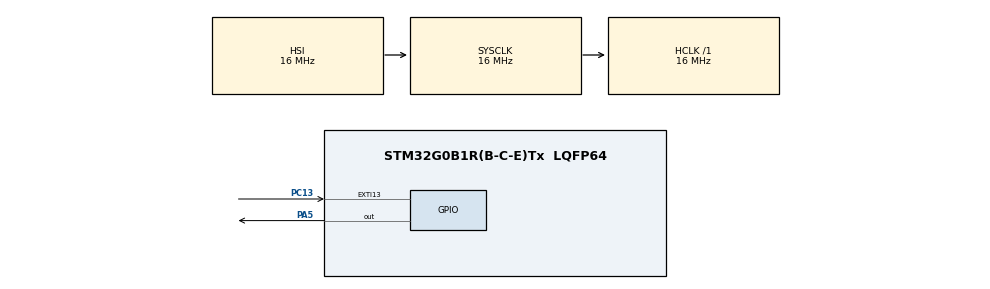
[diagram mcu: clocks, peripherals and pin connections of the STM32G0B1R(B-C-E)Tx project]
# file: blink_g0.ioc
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Mcu.Family=STM32G0
Mcu.Name=STM32G0B1R(B-C-E)Tx
Mcu.Package=LQFP64
NVIC.EXTI4_15_IRQn=true\:0\:0\:false\:false\:true\:true\:true\:true
NVIC.RTC_TAMP_IRQn=true\:0\:0\:false\:false\:true\:true\:true\:true
PA13.GPIO_Label=TMS
PA13.Signal=SYS_SWDIO
PA14-BOOT0.GPIO_Label=TCK
PA14-BOOT0.Signal=SYS_SWCLK
PA2.GPIO_Label=USART2_TX [STLK_TX]
PA2.Signal=USART2_TX
PA3.GPIO_Label=USART2_RX [STLK_RX]
PA3.Signal=USART2_RX
PA5.Signal=GPIO_Output
PC13.Signal=GPXTI13
PC14-OSC32_IN\ (PC14).Mode=LSE-External-Oscillator
PC14-OSC32_IN\ (PC14).Signal=RCC_OSC32_IN
PC15-OSC32_OUT\ (PC15).Mode=LSE-External-Oscillator
PC15-OSC32_OUT\ (PC15).Signal=RCC_OSC32_OUT
PF0-OSC_IN\ (PF0).GPIO_Label=MCO
PF0-OSC_IN\ (PF0).Signal=RCC_OSC_IN
ProjectManager.HeapSize=0x200
ProjectManager.StackSize=0x400
ProjectManager.TargetToolchain=STM32CubeIDE
RCC.AHBFreq_Value=16000000
RCC.CortexFreq_Value=16000000
RCC.EXTERNAL_CLOCK_VALUE=12288000
RCC.HCLKFreq_Value=16000000
RCC.HSE_VALUE=8000000
RCC.HSI48_VALUE=48000000
RCC.HSI_VALUE=16000000
RCC.MSICalibrationValue=18
RCC.RTCClockSelection=RCC_RTCCLKSOURCE_LSE
RCC.SYSCLKFreq_VALUE=16000000
RCC.USBFreq_Value=48000000
RCC.VCOOutputFreq_Value=128000000
RTC.WakeUpCounter-WakeUp=10246
VP_RTC_VS_RTC_Activate.Mode=RTC_Enabled
VP_RTC_VS_RTC_WakeUp_intern.Mode=WakeUp
VP_SYS_VS_DBSignals.Mode=DisableDeadBatterySignals
board=NUCLEO-G0B1RE

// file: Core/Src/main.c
/* USER CODE BEGIN Header */
/**
  ******************************************************************************
  * @file           : main.c
  * @brief          : Main program body
  ******************************************************************************
  * @attention
  *
  * Copyright (c) 2024 STMicroelectronics.
  * All rights reserved.
  *
  * This software is licensed under terms that can be found in the LICENSE file
  * in the root directory of this software component.
  * If no LICENSE file comes with this software, it is provided AS-IS.
  *
  ******************************************************************************
  */
/* USER CODE END Header */
#include "main.h"

/* USER CODE BEGIN PM */

uint8_t PC13_flag = 0;

/* USER CODE END PM */

RTC_HandleTypeDef hrtc;

void SystemClock_Config(void);
static void MX_GPIO_Init(void);
static void MX_RTC_Init(void);

int main(void)
{

  /* MCU Configuration--------------------------------------------------------*/

  /* Reset of all peripherals, Initializes the Flash interface and the Systick. */
  HAL_Init();

  /* Configure the system clock */
  SystemClock_Config();

  /* Initialize all configured peripherals */
  MX_GPIO_Init();
  MX_RTC_Init();
  /* USER CODE BEGIN 2 */

 // HAL_TIM_PWM_Start(&htim2, TIM_CHANNEL_1);

  /* USER CODE END 2 */

  /* Infinite loop */
  while (1)
  {

    /* USER CODE BEGIN 3 */

	  HAL_GPIO_WritePin(GPIOA, GPIO_PIN_5, GPIO_PIN_SET);
	      HAL_Delay(1000);
	      HAL_GPIO_WritePin(GPIOA, GPIO_PIN_5, GPIO_PIN_RESET);

	      // enter STOP mode
	      HAL_PWR_EnterSTOPMode(PWR_LOWPOWERREGULATOR_ON, PWR_STOPENTRY_WFI);

	      // reconfigure system clock
	      SystemClock_Config();
	      /* USER CODE END WHILE */

	      /* USER CODE BEGIN 3 */

	  //HAL_GPIO_TogglePin(GPIOA, GPIO_PIN_5);
	  //HAL_Delay(1000);

  }
  /* USER CODE END 3 */
}

void SystemClock_Config(void)
{
  RCC_OscInitTypeDef RCC_OscInitStruct = {0};
  RCC_ClkInitTypeDef RCC_ClkInitStruct = {0};

  /** Configure the main internal regulator output voltage
  */
  HAL_PWREx_ControlVoltageScaling(PWR_REGULATOR_VOLTAGE_SCALE1);

  /** Configure LSE Drive Capability
  */
  HAL_PWR_EnableBkUpAccess();
  __HAL_RCC_LSEDRIVE_CONFIG(RCC_LSEDRIVE_LOW);

  /** Initializes the RCC Oscillators according to the specified parameters
  * in the RCC_OscInitTypeDef structure.
  */
  RCC_OscInitStruct.OscillatorType = RCC_OSCILLATORTYPE_HSI|RCC_OSCILLATORTYPE_LSE;
  RCC_OscInitStruct.LSEState = RCC_LSE_ON;
  RCC_OscInitStruct.HSIState = RCC_HSI_ON;
  RCC_OscInitStruct.HSIDiv = RCC_HSI_DIV1;
  RCC_OscInitStruct.HSICalibrationValue = RCC_HSICALIBRATION_DEFAULT;
  RCC_OscInitStruct.PLL.PLLState = RCC_PLL_NONE;
  if (HAL_RCC_OscConfig(&RCC_OscInitStruct) != HAL_OK)
  {
    Error_Handler();
  }

  /** Initializes the CPU, AHB and APB buses clocks
  */
  RCC_ClkInitStruct.ClockType = RCC_CLOCKTYPE_HCLK|RCC_CLOCKTYPE_SYSCLK
                              |RCC_CLOCKTYPE_PCLK1;
  RCC_ClkInitStruct.SYSCLKSource = RCC_SYSCLKSOURCE_HSI;
  RCC_ClkInitStruct.AHBCLKDivider = RCC_SYSCLK_DIV1;
  RCC_ClkInitStruct.APB1CLKDivider = RCC_HCLK_DIV1;

  if (HAL_RCC_ClockConfig(&RCC_ClkInitStruct, FLASH_LATENCY_0) != HAL_OK)
  {
    Error_Handler();
  }
}

static void MX_RTC_Init(void)
{

  /** Initialize RTC Only
  */
  hrtc.Instance = RTC;
  hrtc.Init.HourFormat = RTC_HOURFORMAT_24;
  hrtc.Init.AsynchPrediv = 127;
  hrtc.Init.SynchPrediv = 255;
  hrtc.Init.OutPut = RTC_OUTPUT_DISABLE;
  hrtc.Init.OutPutRemap = RTC_OUTPUT_REMAP_NONE;
  hrtc.Init.OutPutPolarity = RTC_OUTPUT_POLARITY_HIGH;
  hrtc.Init.OutPutType = RTC_OUTPUT_TYPE_OPENDRAIN;
  hrtc.Init.OutPutPullUp = RTC_OUTPUT_PULLUP_NONE;
  if (HAL_RTC_Init(&hrtc) != HAL_OK)
  {
    Error_Handler();
  }

  /** Enable the WakeUp
  */
  if (HAL_RTCEx_SetWakeUpTimer_IT(&hrtc, 10246, RTC_WAKEUPCLOCK_RTCCLK_DIV16) != HAL_OK)
  {
    Error_Handler();
  }

}

static void MX_GPIO_Init(void)
{
  GPIO_InitTypeDef GPIO_InitStruct = {0};

  /* GPIO Ports Clock Enable */
  __HAL_RCC_GPIOC_CLK_ENABLE();
  __HAL_RCC_GPIOF_CLK_ENABLE();
  __HAL_RCC_GPIOA_CLK_ENABLE();

  /*Configure GPIO pin Output Level */
  HAL_GPIO_WritePin(GPIOA, GPIO_PIN_5, GPIO_PIN_RESET);

  /*Configure GPIO pin : PC13 */
  GPIO_InitStruct.Pin = GPIO_PIN_13;
  GPIO_InitStruct.Mode = GPIO_MODE_IT_RISING;
  GPIO_InitStruct.Pull = GPIO_NOPULL;
  HAL_GPIO_Init(GPIOC, &GPIO_InitStruct);

  /*Configure GPIO pins : USART2_TX_Pin USART2_RX_Pin */
  GPIO_InitStruct.Pin = USART2_TX_Pin|USART2_RX_Pin;
  GPIO_InitStruct.Mode = GPIO_MODE_AF_PP;
  GPIO_InitStruct.Pull = GPIO_NOPULL;
  GPIO_InitStruct.Speed = GPIO_SPEED_FREQ_LOW;
  GPIO_InitStruct.Alternate = GPIO_AF1_USART2;
  HAL_GPIO_Init(GPIOA, &GPIO_InitStruct);

  /*Configure GPIO pin : PA5 */
  GPIO_InitStruct.Pin = GPIO_PIN_5;
  GPIO_InitStruct.Mode = GPIO_MODE_OUTPUT_PP;
  GPIO_InitStruct.Pull = GPIO_NOPULL;
  GPIO_InitStruct.Speed = GPIO_SPEED_FREQ_LOW;
  HAL_GPIO_Init(GPIOA, &GPIO_InitStruct);

  /* EXTI interrupt init*/
  HAL_NVIC_SetPriority(EXTI4_15_IRQn, 0, 0);
  HAL_NVIC_EnableIRQ(EXTI4_15_IRQn);

}

/* USER CODE BEGIN 4 */
void HAL_GPIO_EXTI_Rising_Callback(uint16_t GPIO_Pin)
{
  PC13_flag++;
  if ( ( PC13_flag & 0x01 ) == 0x01 )
  {
    HAL_GPIO_WritePin(GPIOA, GPIO_PIN_5, GPIO_PIN_SET);
  }
  else
  {
    HAL_GPIO_WritePin(GPIOA, GPIO_PIN_5, GPIO_PIN_RESET);
  }
}

/* USER CODE END 4 */

void Error_Handler(void)
{
  __disable_irq();
  while (1)
  {
  }
}
